# SPC1169 register map
File version: 2022071043481212
CPU: cm4 r1p0, little endian, no MPU, FPU, 4 interrupt priority bits
Registers are 32-bit, read-write, reset 0x0 unless marked. A register's access mark holds for its fields unless they carry their own. Offsets are from the block's base; [hi:lo] are bit positions; 'fields as' and 'values as' point back to an identical list; <NAME> marks a mode.

## CLOCK
Base 0x40000200
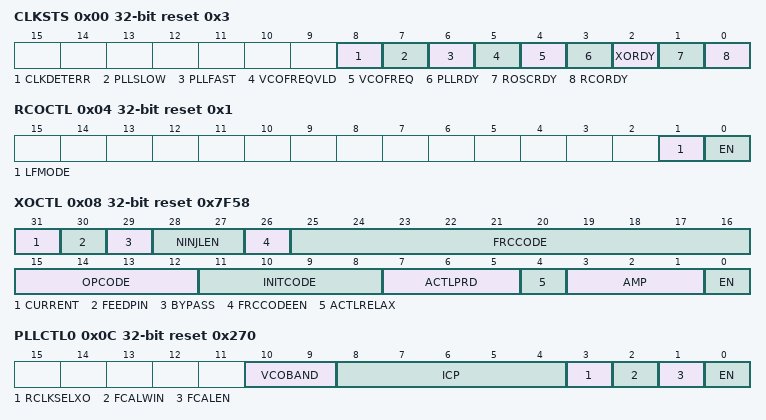
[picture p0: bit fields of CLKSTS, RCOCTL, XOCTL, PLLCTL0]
0x00 CLKSTS ro reset 0x3 — Clock Status Register
  [8] CLKDETERR — Indicate error detected by CLKDET
    0=NOT_OCCUR; 1=OCCUR
  [7] PLLSLOW — Indicate PLL is unlocked and slower than expected. Possible reason can be: 1. Fin/NIN*NFB/65536 is higher than 600MHz (upper boundary of VCO free-running frequency). 2. VCO fails to oscillate. 3. Malfunction of feedback divider so that there is no output or the equivalent dividing ratio is higher than expected
    0=NOT_OCCUR; 1=OCCUR
  [6] PLLFAST — Indicate PLL is unlocked and faster than expected. Possible reason can be: 1. Fin/NIN*NFB/65536 is lower than 400MHz (lower boundary of VCO free-running frequency). 2. The reference clock input is somehow missing. 3. Malfunction of feedback divider so that the equivalent dividing ratio is lower than expected.
    0=NOT_OCCUR; 1=OCCUR
  [5] VCOFREQVLD — VCOFREQ flag valid indicator
    0=INVALID (VCOFREQ is invalid); 1=VALID (VCOFREQ is valid)
  [4] VCOFREQ — VCO frequency flag for trimming
    0=TOO_SLOW (VCO in PLL is too slow); 1=TOO_FAST (VCO in PLL is too fast)
  [3] PLLRDY — PLL clock ready indicator
    0=NOT_READY; 1=READY
  [2] XORDY — XO clock ready indicator
    0=NOT_READY; 1=READY
  [1] ROSCRDY — ROSC clock ready indicator
    0=NOT_READY; 1=READY
  [0] RCORDY — RCO clock ready indicator
    0=NOT_READY; 1=READY
0x04 RCOCTL reset 0x1 — RCO Control Register
  [1] LFMODE — RCO low frequency mode
    0=DISABLE (Normal 32MHz mode (Trimmed)); 1=ENABLE (Low frequency mode (Not trimmed))
  [0] EN — RCO enable
    0=DISABLE; 1=ENABLE
0x08 XOCTL reset 0x7F58 — Crystal Oscillator Control Register
  [31] CURRENT — Current bias option
    0=1x current; 1=2X (2x current)
  [30] FEEDPIN — Pin select in bypass mode
    0=XIN (Apply clock to XIN (GPIO3) pin); 1=XOUT (Apply clock to XOUT (GPIO4) pin)
  [29] BYPASS — Directly feed in the external clock and bypass internal circuit
    0=NORMAL (Internal cricuit is in normal operation); 1=BYPASS (Internal circuit is bypassed)
  [28:27] NINJLEN — Noise injection length
    0=8P7_US (8.7 us); 1=17P4_US (17.4 us); 2=34P8_US (34.8 us); 3=69P6_US (69.6 us)
  [26] FRCCODEEN — Forced amplitude code enable
    0=DISABLE (Amplitude is controlled by the engine); 1=ENABLE (Amplitude is controlled by FRCCODE bits)
  [25:16] FRCCODE — Forced amplitude code
  [15:12] OPCODE — Estimated amplitude code (4MSBs) in operation
  [11:8] INITCODE — Amplitude code (4MSBs) during initial startup
  [7:5] ACTLPRD — Amplitdue control code update period
    0=2048_CYCLE (Update DAC code every 2048 clock cycles); 1=4096_CYCLE (Update DAC code every 4096 clock cycles); 2=8192_CYCLE (Update DAC code every 8192 clock cycles); 3=16384_CYCLE (Update DAC code every 16384 clock cycles); 4=32768_CYCLE (Update DAC code every 32768 clock cycles); 5=65536_CYCLE (Update DAC code every 65536 clock cycles); 6=131072_CYCLE (Update DAC code every 131072 clock cycles); 7=262144_CYCLE (Update DAC code every 262144 clock cycles)
  [4] ACTLRELAX — Relax the threshold of amplitude control
    0=NORMAL (Normal threshold); 1=RELAX (Relaxed threhold)
  [3:1] AMP — Oscillation amplitude when locked
    0=0P32_V (0.32 V); 1=0P48_V (0.48 V); 2=0P64_V (0.64 V); 3=0P77_V (0.77 V); 4=0P92_V (0.92 V); 5=1P06_V (1.06 V); 6=1P19_V (1.19 V); 7=1P33_V (1.33 V)
  [0] EN — Crystal oscillator clock enable
    0=DISABLE; 1=ENABLE
0x0C PLLCTL0 reset 0x270 — PLL Control Register 0
  [10:9] VCOBAND — PLL VCO band control
    0=400MHZ; 1=500MHZ; 2=600MHZ; 3=650MHZ
  [8:4] ICP — PLL charge pump current setting. Must be set to 0.96*NFB/(11-VCOBAND), where NFB is the PLL feedback factor in real number
  [3] RCLKSELXO — PLL reference clock select
    0=RCO (CLK_RCO (RC oscillator)); 1=XO (CLK_XO (Crystal oscillator))
  [2] FCALWIN — PLL frequency calibration time window. For each calibration cycle, keep it as 1 until VCOFREQVLD=1 and release it as 0
    0=DISABLE (Window is disabled); 1=ENABLE (Window is enabled)
  [1] FCALEN — PLL frequency calibration enable
    0=DISABLE; 1=ENABLE
  [0] EN — PLL enable
    0=DISABLE; 1=ENABLE
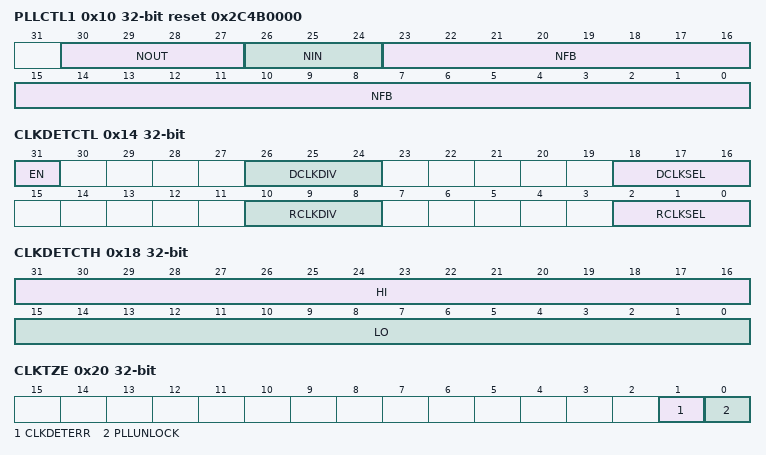
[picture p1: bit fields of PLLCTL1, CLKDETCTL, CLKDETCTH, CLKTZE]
0x10 PLLCTL1 reset 0x2C4B0000 — PLL Control Register 1
  [30:27] NOUT — VCO to digital clock dividing ratio (Fvco/Fout)
  [26:24] NIN — PLL input clock dividing ratio (Fin/Fpfd)
    1=Set to 1 if Fin(MHz) is in [4, 8]: Fin/Fpfd=1; 2=Set to 2 if Fin(MHz) is in (8, 16]: Fin/Fpfd=2; 3=Set to 3 if Fin(MHz) is in (16, 24]: Fin/Fpfd=3; 4=Set to 4 if Fin(MHz) is in (24, 32]: Fin/Fpfd=4; 5=Set to 5 if Fin(MHz) is in (32, 40]: Fin/Fpfd=5; 6=Set to 6 if Fin(MHz) is in (40, 48]: Fin/Fpfd=6; 7=Set to 7 if Fin(MHz) is in (48, 56]: Fin/Fpfd=7
  [23:0] NFB — Feedback dividing ratio (Fvco/Fpfd)
0x14 CLKDETCTL — Clock Detection Control Register
  [31] EN — Clock detection enable. When disabled, the interrupts and the clock error events will be cleared
    0=DISABLE (Disable clock detection); 1=ENABLE (Enable clock detection)
  [26:24] DCLKDIV — Detected clock dividing ratio
    0=Divide by 1; 1=Divide by 2; 2=Divide by 4; 3=Divide by 8; 4=Divide by 16; 5=Divide by 32; 6=Divide by 64; 7=Divide by 128
  [18:16] DCLKSEL — Detected clock select
    0=RCO (RCO clock); 1=ROSC (Ring oscillator clock); 2=XO (Crytal oscillator clock); 3=PLL (PLL clock); 4=LPOSC (Low power ring oscillator clock); 5=EPWRTZ0 (HV clock via ePower TZ0 pin in diagnosis mode); 6=EPWRTZ1 (HV clock via ePower TZ1 pin in diagnosis mode)
  [10:8] RCLKDIV — Reference clock dividing ratio
    values as DCLKDIV
  [2:0] RCLKSEL — Reference clock select
    values as DCLKSEL
0x18 CLKDETCTH — Clock Detection Counter Threshold Register
  [31:16] HI — Upper counter threshold for clock detect. If the final counter value > HI, a trip-zone event will be generated for PWM
  [15:0] LO — Lower counter threshold for clock detect. If the final counter value < LO, a trip-zone event will be generated for PWM
0x1C CLKDETCNT ro — Clock Detection Counter Register
  [15:0] VAL — Final counter value of the clock detect
0x20 CLKTZE — Clock Trip-zone Event Enable Register
  [1] CLKDETERR — CLKDET error trip-zone event enable
    0=DISABLE (CLKDET error will not trigger PWM trip-zone); 1=ENABLE (CLKDET error will trigger PWM trip-zone)
  [0] PLLUNLOCK — PLL unlock trip-zone event enable
    0=DISABLE (PLL unlock will not trigger PWM trip-zone); 1=ENABLE (PLL unlock will trigger PWM trip-zone)
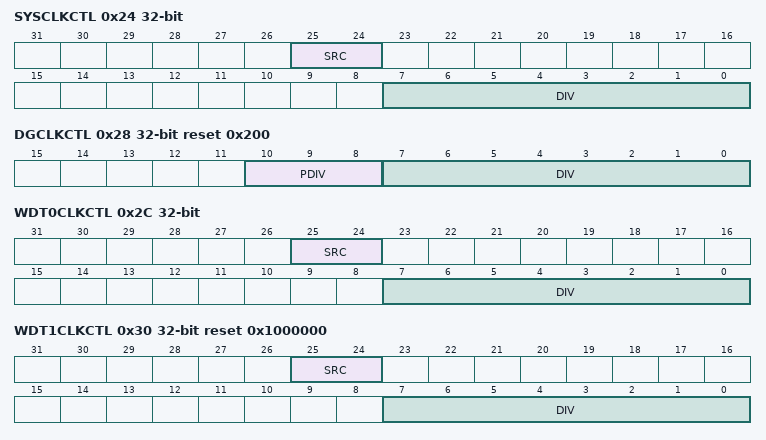
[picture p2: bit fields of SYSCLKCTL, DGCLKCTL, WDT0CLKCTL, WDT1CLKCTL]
0x24 SYSCLKCTL — System Clock Control Register
  [25:24] SRC — Clock source select
    0=RCO; 1=ROSC; 2=XO; 3=PLL
  [7:0] DIV — Clock dividing ratio from the source clock
0x28 DGCLKCTL reset 0x200 — Deglitch Clock Control Register
  [10:8] PDIV — Clock binary pre-dividing ratio from system clock
    values as CLKDETCTL.DCLKDIV
  [7:0] DIV — Clock dividing ratio
0x2C WDT0CLKCTL — WDT0 Clock Control Register
  [25:24] SRC — Clock source select
    0=RCO (RCO clock); 1=ROSC (Ring oscillator clock); 2=XO (Crytal oscillator clock); 3=PLL (PLL clock)
  [7:0] DIV — Clock dividing ratio
0x30 WDT1CLKCTL reset 0x1000000 — WDT1 Clock Control Register
  fields as WDT0CLKCTL
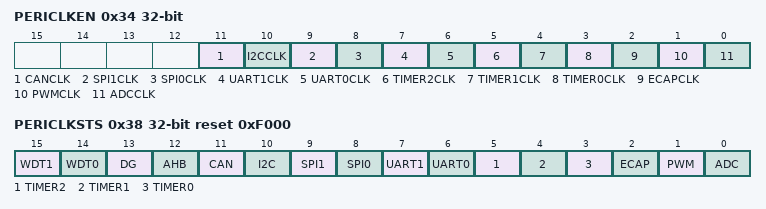
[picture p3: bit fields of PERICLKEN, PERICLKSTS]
0x34 PERICLKEN — Peripheral Clock Enable Register
  [all] fields
    0=DISABLE (Disable clock output); 1=ENABLE (Enable clock output)
  [11] CANCLK — CAN module clock enable
  [10] I2CCLK — I2C module clock enable
  [9] SPI1CLK — SPI1 module clock enable
  [8] SPI0CLK — SPI0 module clock enable
  [7] UART1CLK — UART1 module clock enable
  [6] UART0CLK — UART0 module clock enable
  [5] TIMER2CLK — TIMER2 module clock enable
  [4] TIMER1CLK — TIMER1 module clock enable
  [3] TIMER0CLK — TIMER0 module clock enable
  [2] ECAPCLK — ECAP module clock enable
  [1] PWMCLK — PWM module clock enable
  [0] ADCCLK — ADC module clock enable
0x38 PERICLKSTS ro reset 0xF000 — Peripheral Clock Status Register
  [all] fields
    0=READY; 1=NOT_READY
  [15] WDT1 — Watchdog 1 clock status
  [14] WDT0 — Watchdog 0 clock status
  [13] DG — Deglitch module clock status
  [12] AHB — Bus and CPU clock status
  [11] CAN — CAN module clock status
  [10] I2C — I2C module clock status
  [9] SPI1 — SPI1 module clock status
  [8] SPI0 — SPI0 module clock status
  [7] UART1 — UART1 module clock status
  [6] UART0 — UART0 module clock status
  [5] TIMER2 — TIMER2 module clock status
  [4] TIMER1 — TIMER1 module clock status
  [3] TIMER0 — TIMER0 module clock status
  [2] ECAP — ECAP module clock status
  [1] PWM — PWM module clock status
  [0] ADC — ADC module clock status
0x3C CLKREGKEY reset 0x1ACCE551 — Clock Register Write-Allow Key Register
  [31:0] KEY — Write 0x1ACCE551 to unlock protected clock registers
